# N32H474 register map
Vendor: Nationstech Ltd.; File version: 1.0
Registers are 32-bit, read-write, reset 0x0 unless marked. A register's access mark holds for its fields unless they carry their own. Offsets are from the block's base; [hi:lo] are bit positions; {n}, {i} and the like mark numbered series.

## GPIOA — General purpose I/O
Base 0x4002C000
Same registers: GPIOB 0x4002C400, GPIOC 0x4002C800, GPIOD 0x4002CC00, GPIOE 0x4002D000, GPIOF 0x4002D400, GPIOG 0x4002D800
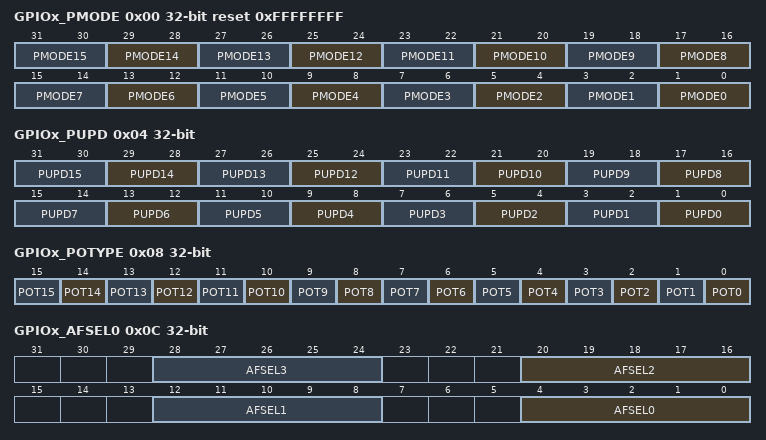
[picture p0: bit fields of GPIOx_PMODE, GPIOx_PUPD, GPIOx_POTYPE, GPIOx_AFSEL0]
0x00 GPIOx_PMODE reset 0xFFFFFFFF
  [2n+1:2n] PMODE{n} (n=0..15)
0x04 GPIOx_PUPD — GPIO pull-up/pull-down description register
  [2n+1:2n] PUPD{n} (n=0..15)
0x08 GPIOx_POTYPE — GPIO output type definition
  [n] POT{n} (n=0..15)
0x0C GPIOx_AFSEL0 — GPIO alternate function select register 0
  [8n+4:8n] AFSEL{n} (n=0..3)
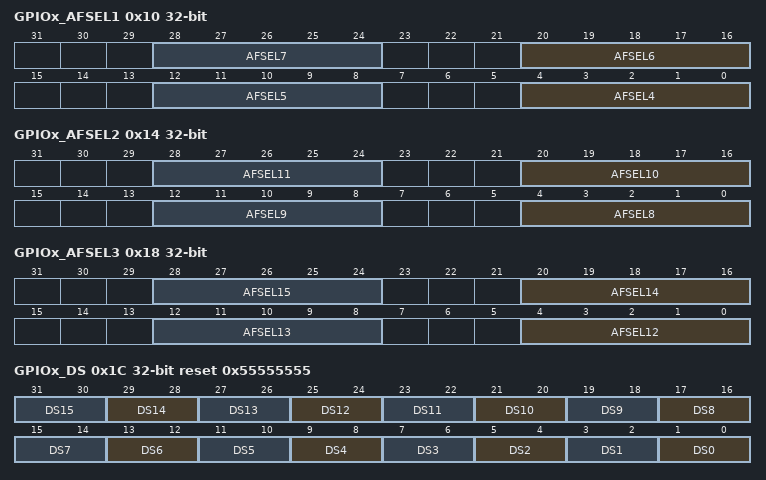
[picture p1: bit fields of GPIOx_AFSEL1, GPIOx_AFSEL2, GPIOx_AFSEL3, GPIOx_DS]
0x10 GPIOx_AFSEL1 — GPIO alternate function select register 1
  [8n-28:8n-32] AFSEL{n} (n=4..7)
0x14 GPIOx_AFSEL2 — GPIO alternate function select register 2
  [8n-60:8n-64] AFSEL{n} (n=8..11)
0x18 GPIOx_AFSEL3 — GPIO alternate function select register 3
  [8n-92:8n-96] AFSEL{n} (n=12..15)
0x1C GPIOx_DS reset 0x55555555 — GPIO driver strength configuration register
  [2n+1:2n] DS{n} (n=0..15)
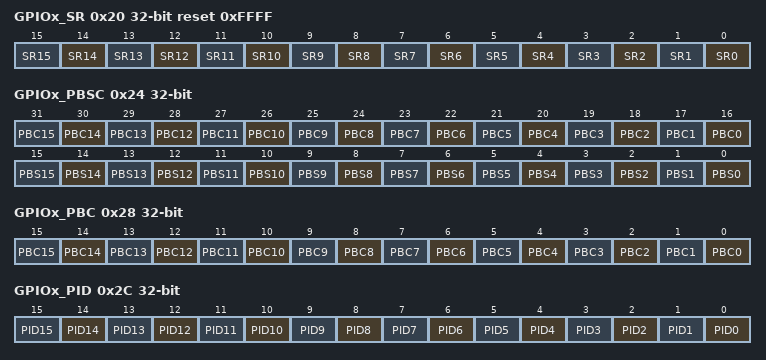
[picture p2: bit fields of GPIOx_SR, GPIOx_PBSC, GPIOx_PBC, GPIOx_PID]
0x20 GPIOx_SR reset 0xFFFF — GPIO slew rate configuration register
  [n] SR{n} (n=0..15)
0x24 GPIOx_PBSC wo — GPIO bit set/clear register
  [n+16] PBC{n} (n=0..15), [n] PBS{n} (n=0..15)
0x28 GPIOx_PBC wo — GPIO bit clear register
  [n] PBC{n} (n=0..15)
0x2C GPIOx_PID ro — GPIO input data register
  [n] PID{n} (n=0..15)
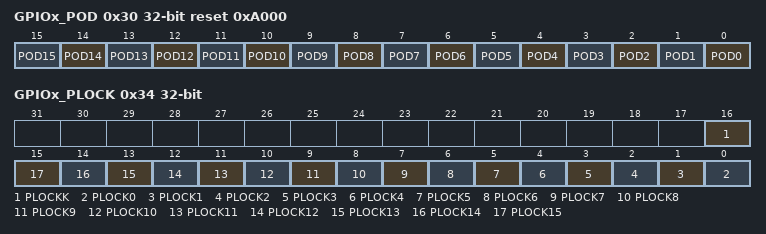
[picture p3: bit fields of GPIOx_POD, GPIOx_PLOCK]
0x30 GPIOx_POD reset 0xA000 — GPIO output data register
  [n] POD{n} (n=0..15)
0x34 GPIOx_PLOCK — GPIO configuration lock register
  [16] PLOCKK, [n] PLOCK{n} (n=0..15)

## GPIOH — General purpose I/O
Base 0x4002DC00
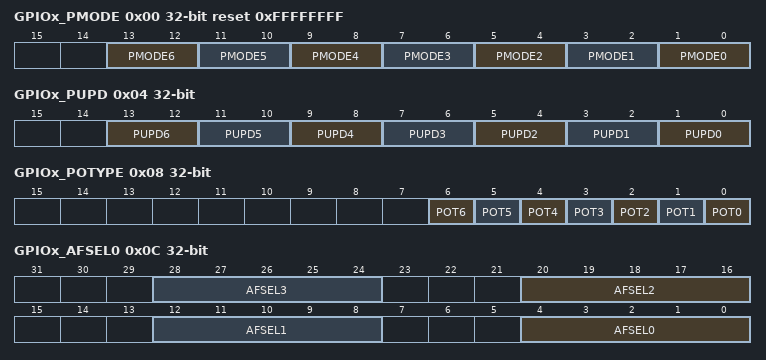
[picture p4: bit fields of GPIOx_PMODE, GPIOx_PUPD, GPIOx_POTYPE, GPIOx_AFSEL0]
0x00 GPIOx_PMODE reset 0xFFFFFFFF — GPIO mode description register
  [2n+1:2n] PMODE{n} (n=0..6)
0x04 GPIOx_PUPD — GPIO pull-up/pull-down description register
  [2n+1:2n] PUPD{n} (n=0..6)
0x08 GPIOx_POTYPE — GPIO output type definition
  [n] POT{n} (n=0..6)
0x0C GPIOx_AFSEL0 — GPIO alternate function select register 0
  [8n+4:8n] AFSEL{n} (n=0..3)
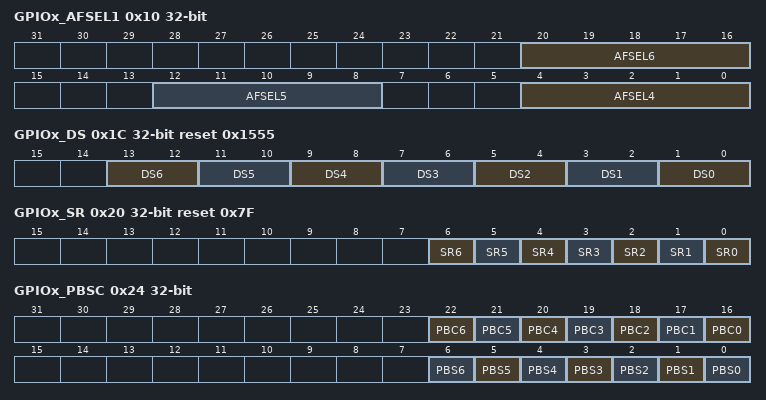
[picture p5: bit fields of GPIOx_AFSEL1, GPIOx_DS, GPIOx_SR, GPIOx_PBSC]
0x10 GPIOx_AFSEL1 — GPIO alternate function select register 1
  [20:16] AFSEL6, [12:8] AFSEL5, [4:0] AFSEL4
0x1C GPIOx_DS reset 0x1555 — GPIO driver strength configuration register
  [2n+1:2n] DS{n} (n=0..6)
0x20 GPIOx_SR reset 0x7F — GPIO slew rate configuration register
  [n] SR{n} (n=0..6)
0x24 GPIOx_PBSC wo — GPIO bit set/clear register
  [n+16] PBC{n} (n=0..6), [n] PBS{n} (n=0..6)
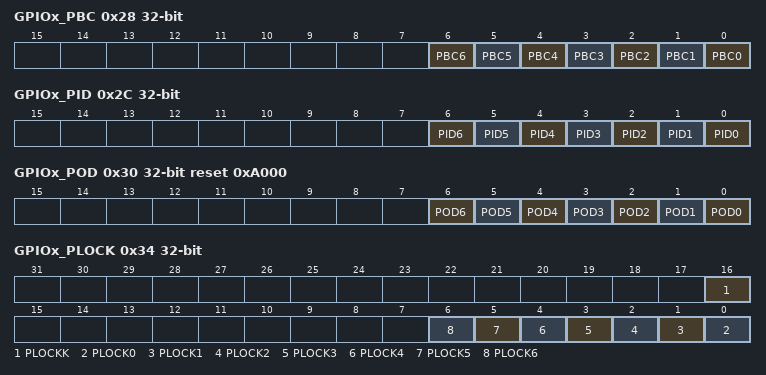
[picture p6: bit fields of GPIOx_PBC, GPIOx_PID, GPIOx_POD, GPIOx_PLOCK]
0x28 GPIOx_PBC wo — GPIO bit clear register
  [n] PBC{n} (n=0..6)
0x2C GPIOx_PID ro — GPIO input data register
  [n] PID{n} (n=0..6)
0x30 GPIOx_POD reset 0xA000 — GPIO output data register
  [n] POD{n} (n=0..6)
0x34 GPIOx_PLOCK — GPIO configuration lock register
  [16] PLOCKK, [n] PLOCK{n} (n=0..6)

## FLASH
Base 0x40022000
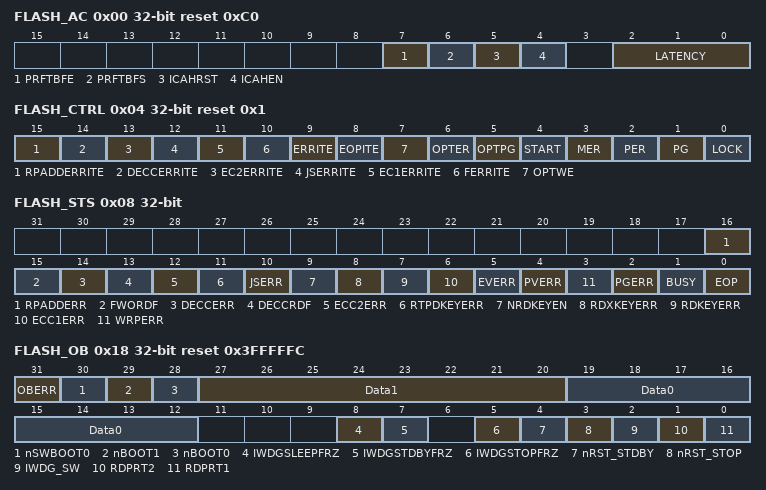
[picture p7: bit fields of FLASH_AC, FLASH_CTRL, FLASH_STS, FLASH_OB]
0x00 FLASH_AC reset 0xC0
  [7] PRFTBFE, [6] PRFTBFS, [5] ICAHRST, [4] ICAHEN, [2:0] LATENCY
0x04 FLASH_CTRL reset 0x1
  [15] RPADDERRITE, [14] DECCERRITE, [13] EC2ERRITE, [12] JSERRITE, [11] EC1ERRITE, [10] FERRITE, [9] ERRITE, [8] EOPITE, [7] OPTWE, [6] OPTER, [5] OPTPG, [4] START, [3] MER, [2] PER, [1] PG, [0] LOCK
0x08 FLASH_STS
  [16] RPADDERR, [15] FWORDF, [14] DECCERR, [13] DECCRDF, [12] ECC2ERR, [11] RTPDKEYERR, [10] JSERR, [9] NRDKEYEN, [8] RDXKEYERR, [7] RDKEYERR, [6] ECC1ERR, [5] EVERR, [4] PVERR, [3] WRPERR, [2] PGERR, [1] BUSY, [0] EOP
0x0C FLASH_ADD
  [31:0] FADD
0x10 FLASH_KEY
  [31:0] FKEY
0x14 FLASH_OPTKEY
0x18 FLASH_OB reset 0x3FFFFFC
  [31] OBERR, [30] nSWBOOT0, [29] nBOOT1, [28] nBOOT0, [27:20] Data1, [19:12] Data0, [8] IWDGSLEEPFRZ, [7] IWDGSTDBYFRZ, [5] IWDGSTOPFRZ, [4] nRST_STDBY, [3] nRST_STOP, [2] IWDG_SW, [1] RDPRT2, [0] RDPRT1
0x1C FLASH_WRP reset 0xFFFFFFFF
  [31:0] WRPT
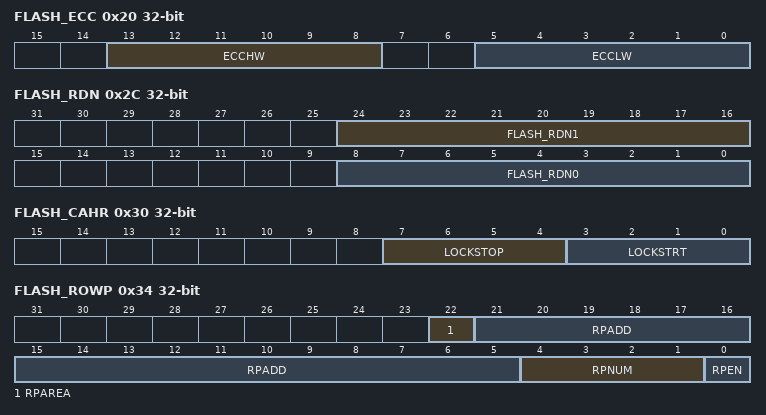
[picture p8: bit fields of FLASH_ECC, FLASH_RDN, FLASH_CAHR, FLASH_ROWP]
0x20 FLASH_ECC
  [13:8] ECCHW, [5:0] ECCLW
0x2C FLASH_RDN
  [24:16] FLASH_RDN1, [8:0] FLASH_RDN0
0x30 FLASH_CAHR
  [7:4] LOCKSTOP, [3:0] LOCKSTRT
0x34 FLASH_ROWP
  [22] RPAREA, [21:5] RPADD, [4:1] RPNUM, [0] RPEN
0x38 CCM_WRP1
  [31:0] WRPTx
0x3C CCM_KEY
  [7:0] KEY
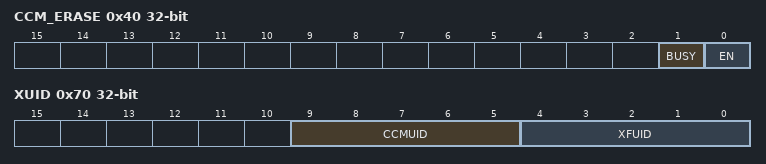
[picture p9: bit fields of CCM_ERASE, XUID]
0x40 CCM_ERASE
  [1] BUSY, [0] EN
0x48 CCM_MODE
  [0] EN
0x4C XSPI_DSTRADD
  [31:0] ADD
0x50 XSPI_DENDADD
  [31:0] ADD
0x54 FEMC_DSTRADD
  [31:0] ADD
0x58 FEMC_DENDADD
  [31:0] ADD
0x5C RTPD_KEY
0x60 JTAG_SEAL
  [7:0] DATA
0x64 RTPD_KEY_WCNT
  [2:0] CNT
0x6C XSPI_FEMC_DEN
  [0] EN
0x70 XUID
  [9:5] CCMUID, [4:0] XFUID
